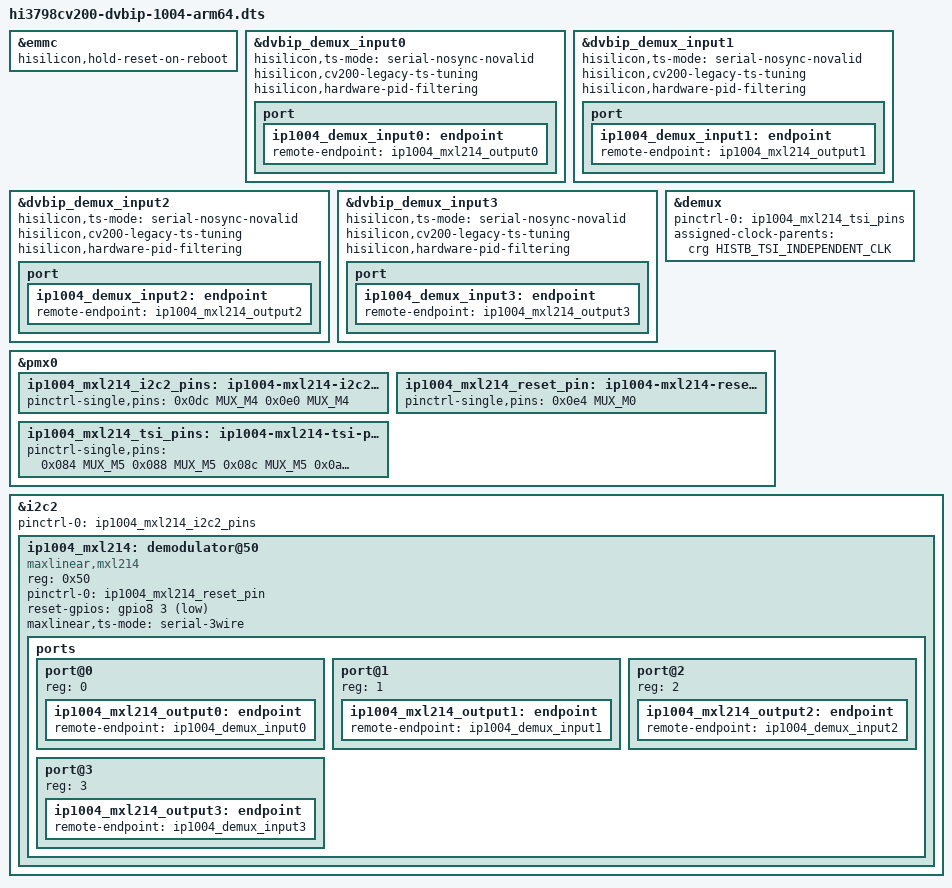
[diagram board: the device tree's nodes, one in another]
// SPDX-License-Identifier: GPL-2.0-only
/*
 * Device Tree Source for HiSilicon Hi3798CV200 DVBIP-1004 board.
 */

/dts-v1/;

#include "hi3798cv200-dvbip-1004.dtsi"

/* Keep the 8GME4R in reset for the original bootloader's warm-reboot path. */
&emmc {
	hisilicon,hold-reset-on-reboot;
};

/* The fitted MxL214 uses four independent three-wire outputs. */
&dvbip_demux_input0 {
	status = "okay";
	/delete-property/ hisilicon,clock-inverted;
	hisilicon,ts-mode = "serial-nosync-novalid";
	hisilicon,cv200-legacy-ts-tuning;
	hisilicon,hardware-pid-filtering;

	port {
		ip1004_demux_input0: endpoint {
			remote-endpoint = <&ip1004_mxl214_output0>;
		};
	};
};

&dvbip_demux_input1 {
	status = "okay";
	hisilicon,ts-mode = "serial-nosync-novalid";
	hisilicon,cv200-legacy-ts-tuning;
	hisilicon,hardware-pid-filtering;

	port {
		ip1004_demux_input1: endpoint {
			remote-endpoint = <&ip1004_mxl214_output1>;
		};
	};
};

&dvbip_demux_input2 {
	status = "okay";
	/delete-property/ hisilicon,clock-inverted;
	hisilicon,ts-mode = "serial-nosync-novalid";
	hisilicon,cv200-legacy-ts-tuning;
	hisilicon,hardware-pid-filtering;

	port {
		ip1004_demux_input2: endpoint {
			remote-endpoint = <&ip1004_mxl214_output2>;
		};
	};
};

&dvbip_demux_input3 {
	status = "okay";
	hisilicon,ts-mode = "serial-nosync-novalid";
	hisilicon,cv200-legacy-ts-tuning;
	hisilicon,hardware-pid-filtering;

	port {
		ip1004_demux_input3: endpoint {
			remote-endpoint = <&ip1004_mxl214_output3>;
		};
	};
};

/* OTA device-2/mxl214C_3wire: tuner N -> TSI N, no common clock. */
&demux {
	pinctrl-names = "default";
	pinctrl-0 = <&ip1004_mxl214_tsi_pins>;
	assigned-clock-parents = <&crg HISTB_TSI_INDEPENDENT_CLK>;
};

&pmx0 {
	ip1004_mxl214_i2c2_pins: ip1004-mxl214-i2c2-pins {
		pinctrl-single,pins = <
			0x0dc MUX_M4 /* I2C2_SCL */
			0x0e0 MUX_M4 /* I2C2_SDA */
		>;
	};

	ip1004_mxl214_reset_pin: ip1004-mxl214-reset-pin {
		pinctrl-single,pins = <
			0x0e4 MUX_M0 /* GPIO8_3 / global GPIO67, active-low reset */
		>;
	};

	ip1004_mxl214_tsi_pins: ip1004-mxl214-tsi-pins {
		pinctrl-single,pins = <
			0x084 MUX_M5 /* TSI3_SYNC */
			0x088 MUX_M5 /* TSI3_D0 */
			0x08c MUX_M5 /* TSI3_CLK */
			0x0a0 MUX_M5 /* TSI2_SYNC */
			0x0a4 MUX_M5 /* TSI2_D0 */
			0x0a8 MUX_M5 /* TSI2_CLK */
			0x0cc MUX_M5 /* TSI1_SYNC */
			0x0d0 MUX_M5 /* TSI1_D0 */
			0x0d4 MUX_M5 /* TSI1_CLK */
			0x0e8 MUX_M5 /* TSI0_SYNC */
			0x0ec MUX_M5 /* TSI0_D0 */
			0x0f0 MUX_M5 /* TSI0_CLK */
		>;
	};
};


&i2c2 {
	pinctrl-names = "default";
	pinctrl-0 = <&ip1004_mxl214_i2c2_pins>;
	status = "okay";

	ip1004_mxl214: demodulator@50 {
		compatible = "maxlinear,mxl214";
		reg = <0x50>;
		pinctrl-names = "default";
		pinctrl-0 = <&ip1004_mxl214_reset_pin>;
		reset-gpios = <&gpio8 3 GPIO_ACTIVE_LOW>;
		maxlinear,ts-mode = "serial-3wire";

		ports {
			#address-cells = <1>;
			#size-cells = <0>;

			port@0 {
				reg = <0>;
				ip1004_mxl214_output0: endpoint {
					remote-endpoint = <&ip1004_demux_input0>;
				};
			};

			port@1 {
				reg = <1>;
				ip1004_mxl214_output1: endpoint {
					remote-endpoint = <&ip1004_demux_input1>;
				};
			};

			port@2 {
				reg = <2>;
				ip1004_mxl214_output2: endpoint {
					remote-endpoint = <&ip1004_demux_input2>;
				};
			};

			port@3 {
				reg = <3>;
				ip1004_mxl214_output3: endpoint {
					remote-endpoint = <&ip1004_demux_input3>;
				};
			};
		};
	};
};
